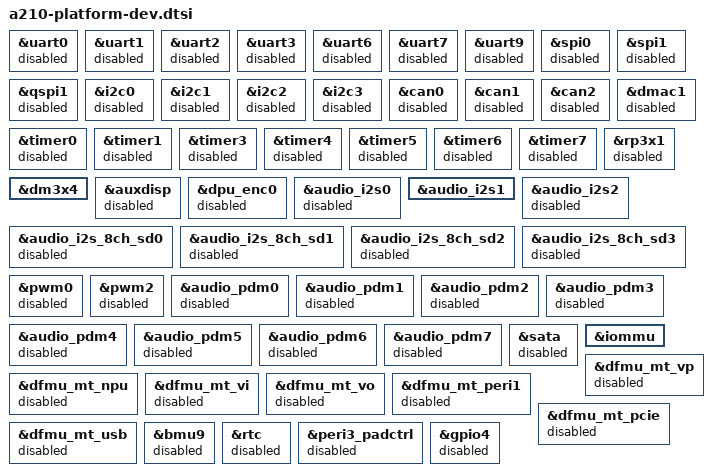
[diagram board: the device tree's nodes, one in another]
&uart0 {
	status = "disabled";
};

&uart1 {
	status = "disabled";
};

&uart2 {
	status = "disabled";
};

&uart3 {
	status = "disabled";
};

&uart6 {
	status = "disabled";
};

&uart7 {
	status = "disabled";
};

&uart9 {
	status = "disabled";
};

&spi0 {
	status = "disabled";
};

&spi1 {
	status = "disabled";
};

&qspi1 {
	status = "disabled";
};

&i2c0 {
	status = "disabled";
};

&i2c1 {
	status = "disabled";
};

&i2c2 {
	status = "disabled";
};

&i2c3 {
	status = "disabled";
};

&can0 {
	status = "disabled";
};

&can1 {
	status = "disabled";
};

&can2 {
	status = "disabled";
};

&dmac1 {
	status = "disabled";
};

&timer0 {
	status = "disabled";
};

&timer1 {
	status = "disabled";
};

&timer3 {
	status = "disabled";
};

&timer4 {
	status = "disabled";
};

&timer5 {
	status = "disabled";
};

&timer6 {
	status = "disabled";
};

&timer7 {
	status = "disabled";
};

&rp3x1 {
	status = "disabled";
};

&dm3x4 {
	status = "okay";
};

&auxdisp {
	status = "disabled";
};

&dpu_enc0 {
	status = "disabled";
};

&audio_i2s0 {
	status = "disabled";
};

&audio_i2s1 {
	status = "okay";
};

&audio_i2s2 {
	status = "disabled";
};

&audio_i2s_8ch_sd0 {
	status = "disabled";
};

&audio_i2s_8ch_sd1 {
	status = "disabled";
};

&audio_i2s_8ch_sd2 {
	status = "disabled";
};

&audio_i2s_8ch_sd3 {
	status = "disabled";
};

&pwm0 {
	status = "disabled";
};

&pwm2 {
	status = "disabled";
};

&audio_pdm0 {
	status = "disabled";
};

&audio_pdm1 {
	status = "disabled";
};

&audio_pdm2 {
	status = "disabled";
};

&audio_pdm3 {
	status = "disabled";
};

&audio_pdm4 {
	status = "disabled";
};

&audio_pdm5 {
	status = "disabled";
};

&audio_pdm6 {
	status = "disabled";
};

&audio_pdm7 {
	status = "disabled";
};

&sata {
	status = "disabled";
};

/* dfmu/iommu */
&iommu {
	status = "okay";
};

&dfmu_mt_vp {
	status = "disabled";
};

&dfmu_mt_npu {
	status = "disabled";
};

&dfmu_mt_vi {
	status = "disabled";
};

&dfmu_mt_vo {
	status = "disabled";
};

&dfmu_mt_peri1 {
	status = "disabled";
};

&dfmu_mt_pcie {
	status = "disabled";
};

&dfmu_mt_usb {
	status = "disabled";
};

&bmu9 {
	status = "disabled";
};

&rtc {
	status = "disabled";
};

/* Temporarily disable gpio4 */
&peri3_padctrl {
	status = "disabled";
};

&gpio4 {
	status = "disabled";
};
